# MKV44F15 register map
Vendor: Freescale Semiconductor, Inc.; Series: Kinetis_V; File version: 1.6
CPU: CM4 r0p1, little endian, no MPU, FPU, VTOR, 4 interrupt priority bits
Registers are 8-bit, read-write, reset 0x0 unless marked. A register's access mark holds for its fields unless they carry their own. Offsets are from the block's base; [hi:lo] are bit positions; 'fields as' and 'values as' point back to an identical list.

## SysTick — System timer
Base 0xE000E010; register names take the prefix SYST_
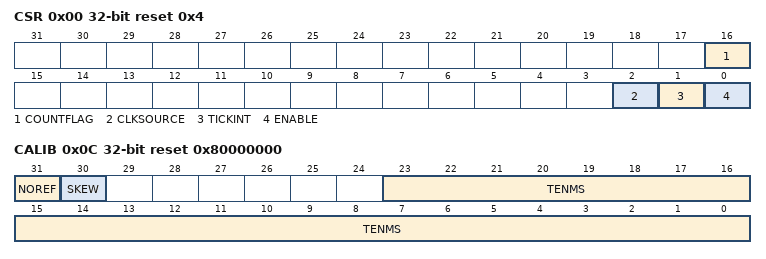
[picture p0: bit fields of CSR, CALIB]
0x00 CSR 32-bit reset 0x4 — SysTick Control and Status Register
  [16] COUNTFLAG
  [2] CLKSOURCE
    0=external clock; 1=processor clock
  [1] TICKINT
    0=counting down to 0 does not assert the SysTick exception request; 1=counting down to 0 asserts the SysTick exception request
  [0] ENABLE
    0=counter disabled; 1=counter enabled
0x04 RVR 32-bit — SysTick Reload Value Register
  [23:0] RELOAD — Value to load into the SysTick Current Value Register when the counter reaches 0
0x08 CVR 32-bit — SysTick Current Value Register
  [23:0] CURRENT — Current value at the time the register is accessed
0x0C CALIB 32-bit ro reset 0x80000000 — SysTick Calibration Value Register
  [31] NOREF
    0=The reference clock is provided; 1=The reference clock is not provided
  [30] SKEW
    0=10ms calibration value is exact; 1=10ms calibration value is inexact, because of the clock frequency
  [23:0] TENMS — Reload value to use for 10ms timing

## MCM — Core Platform Miscellaneous Control Module
Base 0xE0080000; register names take the prefix MCM_
0x08 PLASC 16-bit ro reset 0xF — Crossbar Switch (AXBS) Slave Configuration
  [7:0] ASC — Each bit in the ASC field indicates whether there is a corresponding connection to the crossbar switch's slave input port.
    0=A bus slave connection to AXBS input port n is absent; 1=A bus slave connection to AXBS input port n is present
0x0A PLAMC 16-bit ro reset 0x7 — Crossbar Switch (AXBS) Master Configuration
  [7:0] AMC — Each bit in the AMC field indicates whether there is a corresponding connection to the AXBS master input port.
    0=A bus master connection to AXBS input port n is absent; 1=A bus master connection to AXBS input port n is present
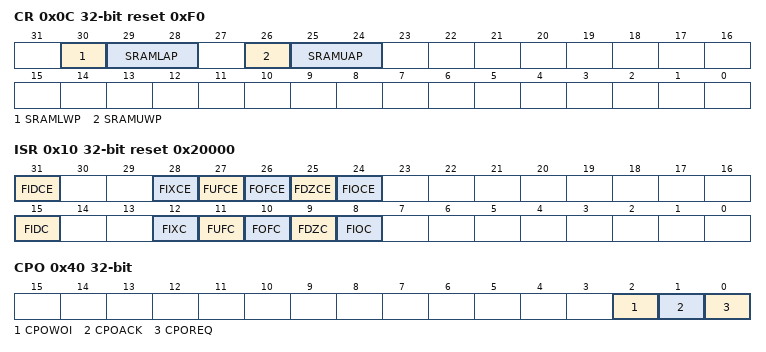
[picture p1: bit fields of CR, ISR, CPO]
0x0C CR 32-bit reset 0xF0 — Control Register
  [30] SRAMLWP — SRAM_L Write Protect
  [29:28] SRAMLAP — SRAM_L arbitration priority
    0=Round robin; 1=Special round robin (favors SRAM backoor accesses over the processor); 2=Fixed priority. Processor has highest, backdoor has lowest; 3=Fixed priority. Backdoor has highest, processor has lowest
  [26] SRAMUWP — SRAM_U write protect
  [25:24] SRAMUAP — SRAM_U arbitration priority
    values as SRAMLAP
0x10 ISR 32-bit reset 0x20000 — Interrupt Status Register
  [31] FIDCE — FPU input denormal interrupt enable
    0=Disable interrupt; 1=Enable interrupt
  [28] FIXCE — FPU inexact interrupt enable
    0=Disable interrupt; 1=Enable interrupt
  [27] FUFCE — FPU underflow interrupt enable
    0=Disable interrupt; 1=Enable interrupt
  [26] FOFCE — FPU overflow interrupt enable
    0=Disable interrupt; 1=Enable interrupt
  [25] FDZCE — FPU divide-by-zero interrupt enable
    0=Disable interrupt; 1=Enable interrupt
  [24] FIOCE — FPU invalid operation interrupt enable
    0=Disable interrupt; 1=Enable interrupt
  [15] FIDC ro — FPU input denormal interrupt status
    0=No interrupt; 1=Interrupt occurred
  [12] FIXC ro — FPU inexact interrupt status
    0=No interrupt; 1=Interrupt occurred
  [11] FUFC ro — FPU underflow interrupt status
    0=No interrupt; 1=Interrupt occurred
  [10] FOFC ro — FPU overflow interrupt status
    0=No interrupt; 1=Interrupt occurred
  [9] FDZC ro — FPU divide-by-zero interrupt status
    0=No interrupt; 1=Interrupt occurred
  [8] FIOC ro — FPU invalid operation interrupt status
    0=No interrupt; 1=Interrupt occurred
0x40 CPO 32-bit — Compute Operation Control Register
  [2] CPOWOI — Compute Operation wakeup on interrupt
    0=No effect; 1=When set, the CPOREQ is cleared on any interrupt or exception vector fetch
  [1] CPOACK ro — Compute Operation acknowledge
    0=Compute operation entry has not completed or compute operation exit has completed; 1=Compute operation entry has completed or compute operation exit has not completed
  [0] CPOREQ — Compute Operation request
    0=Request is cleared; 1=Request Compute Operation
